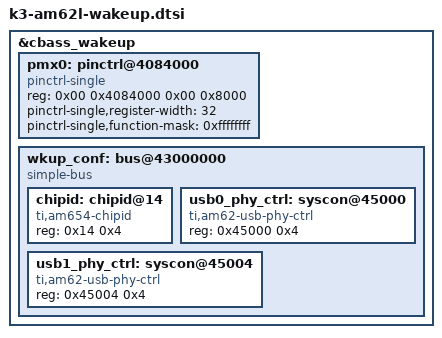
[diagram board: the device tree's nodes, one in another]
// SPDX-License-Identifier: GPL-2.0-only or MIT
/*
 * Device Tree file for the AM62L wakeup domain peripherals
 * Copyright (C) 2024 Texas Instruments Incorporated - https://www.ti.com/
 *
 * Technical Reference Manual: https://www.ti.com/lit/pdf/sprujb4
 */

&cbass_wakeup {
	pmx0: pinctrl@4084000 {
		compatible = "pinctrl-single";
		reg = <0x00 0x4084000 0x00 0x8000>;
		pinctrl-single,register-width = <32>;
		pinctrl-single,function-mask = <0xffffffff>;
		#pinctrl-cells = <1>;
		bootph-all;
	};

	wkup_conf: bus@43000000 {
		compatible = "simple-bus";
		ranges = <0x0 0x00 0x43000000 0x80000>;
		#address-cells = <1>;
		#size-cells = <1>;

		chipid: chipid@14 {
			compatible = "ti,am654-chipid";
			reg = <0x14 0x4>;
			bootph-all;
		};

		usb0_phy_ctrl: syscon@45000 {
			compatible = "ti,am62-usb-phy-ctrl", "syscon";
			reg = <0x45000 0x4>;
			bootph-all;
		};

		usb1_phy_ctrl: syscon@45004 {
			compatible = "ti,am62-usb-phy-ctrl", "syscon";
			reg = <0x45004 0x4>;
		};
	};
};

